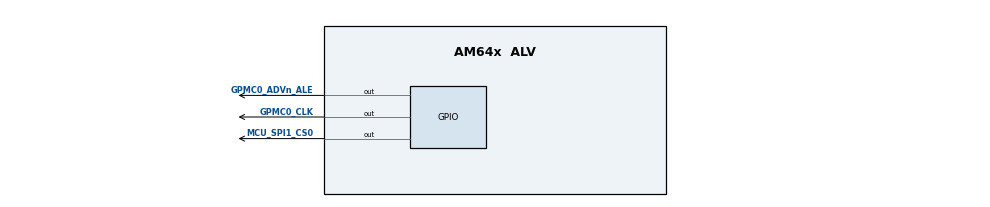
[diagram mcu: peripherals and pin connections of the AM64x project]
/**
 * @cliArgs --device "AM64x" --package "ALV" --part "Default" --context "r5fss0-0" --product "MCU_PLUS_SDK@07.03.01"
 * @versions {"tool":"1.20.0+3587"}
 */

/**
 * Import the modules used in this configuration.
 */
const eeprom     = scripting.addModule("/board/eeprom/eeprom", {}, false);
const eeprom1    = eeprom.addInstance();
const gpio       = scripting.addModule("/drivers/gpio/gpio", {}, false);
const gpio1      = gpio.addInstance();
const gpio2      = gpio.addInstance();
const gpio3      = gpio.addInstance();
const i2c        = scripting.addModule("/drivers/i2c/i2c", {}, false);
const i2c1       = i2c.addInstance();
const i2c2       = i2c.addInstance();
const ipc        = scripting.addModule("/drivers/ipc/ipc");
const pruicss    = scripting.addModule("/drivers/pruicss/pruicss", {}, false);
const pruicss1   = pruicss.addInstance();
const pruicss2   = pruicss.addInstance();
const debug_log  = scripting.addModule("/kernel/dpl/debug_log");
const dpl_cfg = scripting.addModule("/kernel/dpl/dpl_cfg");
const mpu_armv7  = scripting.addModule("/kernel/dpl/mpu_armv7", {}, false);
const mpu_armv71 = mpu_armv7.addInstance();
const mpu_armv72 = mpu_armv7.addInstance();
const mpu_armv73 = mpu_armv7.addInstance();
const mpu_armv74 = mpu_armv7.addInstance();
const mpu_armv75 = mpu_armv7.addInstance();
const mpu_armv76 = mpu_armv7.addInstance();
const mpu_armv77 = mpu_armv7.addInstance();
const mpu_armv78 = mpu_armv7.addInstance();
const enet_icss  = scripting.addModule("/networking/enet_icss/enet_icss", {}, false);
const enet_icss1 = enet_icss.addInstance();
const enet_icss2 = enet_icss.addInstance();
const enet_icss3 = enet_icss.addInstance();
const enet_icss4 = enet_icss.addInstance();

/**
 * Write custom configuration values to the imported modules.
 */
eeprom1.$name = "CONFIG_EEPROM0";

gpio1.$name                    = "CONFIG_GPIO0";
gpio1.pinDir                   = "OUTPUT";
gpio1.useMcuDomainPeripherals  = true;
gpio1.MCU_GPIO.$assign         = "MCU_GPIO0";
gpio1.MCU_GPIO.gpioPin.$assign = "MCU_SPI1_CS0";

gpio2.$name                = "CONFIG_GPIO_31";
gpio2.pinDir               = "OUTPUT";
gpio2.GPIO.$assign         = "GPIO0";
gpio2.GPIO.gpioPin.pu_pd   = "pu";
gpio2.GPIO.gpioPin.$assign = "GPMC0_CLK";

gpio3.$name                = "CONFIG_GPIO_32";
gpio3.pinDir               = "OUTPUT";
gpio3.GPIO.$assign         = "GPIO0";
gpio3.GPIO.gpioPin.pu_pd   = "pu";
gpio3.GPIO.gpioPin.$assign = "GPMC0_ADVn_ALE";

i2c1.$name               = "CONFIG_I2C0";
eeprom1.peripheralDriver = i2c1;
i2c1.I2C.$assign         = "I2C0";
i2c1.I2C.SCL.$assign     = "I2C0_SCL";
i2c1.I2C.SDA.$assign     = "I2C0_SDA";
i2c1.I2C_child.$name     = "drivers_i2c_v0_i2c_v0_template1";

i2c2.$name           = "CONFIG_I2C1";
i2c2.I2C.$assign     = "I2C1";
i2c2.I2C.SCL.$assign = "I2C1_SCL";
i2c2.I2C.SDA.$assign = "I2C1_SDA";
i2c2.I2C_child.$name = "drivers_i2c_v0_i2c_v0_template2";

ipc.r5fss1_0     = "NONE";
ipc.r5fss1_1     = "NONE";
ipc.m4fss0_0     = "NONE";
ipc.vringMsgSize = 1024;

debug_log.enableCssLog  = false;
debug_log.enableUartLog = true;
debug_log.uartLog.$name = "CONFIG_UART0";

const uart_v0_template  = scripting.addModule("/drivers/uart/v0/uart_v0_template", {}, false);
const uart_v0_template1 = uart_v0_template.addInstance({}, false);
uart_v0_template1.$name = "drivers_uart_v0_uart_v0_template0";
debug_log.uartLog.child = uart_v0_template1;

mpu_armv71.$name             = "CONFIG_MPU_REGION0";
mpu_armv71.size              = 31;
mpu_armv71.attributes        = "Device";
mpu_armv71.accessPermissions = "Supervisor RD+WR, User RD";
mpu_armv71.allowExecute      = false;

mpu_armv72.$name             = "CONFIG_MPU_REGION1";
mpu_armv72.size              = 15;
mpu_armv72.accessPermissions = "Supervisor RD+WR, User RD";

mpu_armv73.$name             = "CONFIG_MPU_REGION2";
mpu_armv73.baseAddr          = 0x41010000;
mpu_armv73.size              = 15;
mpu_armv73.accessPermissions = "Supervisor RD+WR, User RD";

mpu_armv74.$name             = "CONFIG_MPU_REGION3";
mpu_armv74.accessPermissions = "Supervisor RD+WR, User RD";
mpu_armv74.baseAddr          = 0x70000000;
mpu_armv74.attributes        = "NonCached";
mpu_armv74.size              = 21;

mpu_armv75.$name             = "CONFIG_MPU_REGION4";
mpu_armv75.accessPermissions = "Supervisor RD+WR, User RD";
mpu_armv75.baseAddr          = 0x80000000;
mpu_armv75.size              = 31;

mpu_armv76.$name             = "CONFIG_MPU_REGION5";
mpu_armv76.accessPermissions = "Supervisor RD+WR, User RD";
mpu_armv76.baseAddr          = 0xA5000000;
mpu_armv76.size              = 23;
mpu_armv76.attributes        = "NonCached";

mpu_armv77.$name    = "CONFIG_MPU_REGION6";
mpu_armv77.size     = 27;
mpu_armv77.baseAddr = 0x60000000;

mpu_armv78.$name      = "CONFIG_MPU_REGION7";
mpu_armv78.attributes = "NonCached";
mpu_armv78.size       = 16;
mpu_armv78.baseAddr   = 0x701D0000;

enet_icss1.$name                        = "CONFIG_ENET_ICSS0";
enet_icss1.LargePoolPktCount            = 16;
enet_icss1.PktInfoOnlyEnable            = true;
enet_icss1.mdioPollEnMask               = [];
enet_icss1.mdioMode                     = "MDIO_MODE_NORMAL";
enet_icss1.mode                         = "DUAL MAC";
enet_icss1.phyToMacInterfaceMode        = "RGMII";
enet_icss1.txDmaChannel[0].$name        = "ENET_DMA_TX_CH1";
enet_icss1.netifInstance.create(1);
enet_icss1.netifInstance[0].$name       = "NETIF_INST_ID0";
enet_icss1.rxDmaChannel[0].$name        = "ENET_DMA_RX_CH0";
enet_icss1.rxDmaChannel[0].PacketsCount = 16;

enet_icss2.$name                        = "CONFIG_ENET_ICSS1";
enet_icss2.LargePoolPktCount            = 16;
enet_icss2.PktInfoOnlyEnable            = true;
enet_icss2.mode                         = "DUAL MAC";
enet_icss2.mdioMdcEnable                = false;
enet_icss2.dualMacPortSelected          = "ENET_MAC_PORT_2";
enet_icss2.phyToMacInterfaceMode        = "RGMII";
enet_icss2.mdioPollEnMask               = [];
enet_icss2.mdioMode                     = "MDIO_MODE_NORMAL";
enet_icss2.txDmaChannel[0].$name        = "ENET_DMA_TX_CH0";
enet_icss2.netifInstance.create(1);
enet_icss2.netifInstance[0].$name       = "NETIF_INST_ID1";
enet_icss2.rxDmaChannel[0].$name        = "ENET_DMA_RX_CH1";
enet_icss2.rxDmaChannel[0].PacketsCount = 16;

pruicss2.$name                           = "CONFIG_PRU_ICSS1";
pruicss2.instance                        = "ICSSG1";
pruicss2.coreClk                         = 250000000;
enet_icss1.icss                          = pruicss2;
enet_icss2.icss                          = pruicss2;
pruicss2.AdditionalICSSSettings[0].$name = "CONFIG_PRU_ICSS_IO2";
pruicss2.intcMapping.create(2);
pruicss2.intcMapping[0].$name            = "CONFIG_ICSS1_INTC_MAPPING0";
pruicss2.intcMapping[0].event            = "41";
pruicss2.intcMapping[0].channel          = "7";
pruicss2.intcMapping[1].$name            = "CONFIG_ICSS1_INTC_MAPPING1";
pruicss2.intcMapping[1].event            = "53";
pruicss2.intcMapping[1].channel          = "7";

enet_icss3.$name                              = "CONFIG_ENET_ICSS2";
enet_icss3.mode                               = "DUAL MAC";
enet_icss3.PktInfoOnlyEnable                  = true;
enet_icss3.LargePoolPktCount                  = 16;
enet_icss3.instance                           = "ICSSG0";
enet_icss3.mdioPollEnMask                     = [];
enet_icss3.mdioMode                           = "MDIO_MODE_NORMAL";
enet_icss3.phyAddr1                           = 1;
enet_icss3.GigabitSupportEnable               = false;
enet_icss3.txDmaChannel[0].$name              = "ENET_DMA_TX_CH2";
enet_icss3.netifInstance.create(1);
enet_icss3.netifInstance[0].$name             = "NETIF_INST_ID2";
enet_icss3.rxDmaChannel[0].$name              = "ENET_DMA_RX_CH4";
enet_icss3.rxDmaChannel[0].PacketsCount       = 16;
enet_icss3.PRU_ICSSG0_MII_G_RT.MII0_COL.$used = false;
enet_icss3.PRU_ICSSG0_MII_G_RT.MII0_CRS.$used = false;
enet_icss3.PRU_ICSSG0_MII_G_RT.MII1_COL.$used = false;
enet_icss3.PRU_ICSSG0_MII_G_RT.MII1_CRS.$used = false;

enet_icss4.$name                        = "CONFIG_ENET_ICSS3";
enet_icss4.mode                         = "DUAL MAC";
enet_icss4.mdioMdcEnable                = false;
enet_icss4.dualMacPortSelected          = "ENET_MAC_PORT_2";
enet_icss4.LargePoolPktCount            = 16;
enet_icss4.PktInfoOnlyEnable            = true;
enet_icss4.instance                     = "ICSSG0";
enet_icss4.mdioPollEnMask               = [];
enet_icss4.mdioMode                     = "MDIO_MODE_NORMAL";
enet_icss4.phyAddr1                     = 1;
enet_icss4.GigabitSupportEnable         = false;
enet_icss4.txDmaChannel[0].$name        = "ENET_DMA_TX_CH3";
enet_icss4.netifInstance.create(1);
enet_icss4.netifInstance[0].$name       = "NETIF_INST_ID3";
enet_icss4.rxDmaChannel[0].$name        = "ENET_DMA_RX_CH5";
enet_icss4.rxDmaChannel[0].PacketsCount = 16;

pruicss1.$name                           = "CONFIG_PRU_ICSS0";
pruicss1.coreClk                         = 250000000;
enet_icss3.icss                          = pruicss1;
enet_icss4.icss                          = pruicss1;
pruicss1.AdditionalICSSSettings[0].$name = "CONFIG_PRU_ICSS_IO1";
pruicss1.intcMapping.create(2);
pruicss1.intcMapping[0].$name            = "CONFIG_ICSS0_INTC_MAPPING0";
pruicss1.intcMapping[0].event            = "41";
pruicss1.intcMapping[0].channel          = "7";
pruicss1.intcMapping[1].$name            = "CONFIG_ICSS0_INTC_MAPPING1";
pruicss1.intcMapping[1].event            = "53";
pruicss1.intcMapping[1].channel          = "7";

const udma         = scripting.addModule("/drivers/udma/udma", {}, false);
const udma1        = udma.addInstance({}, false);
enet_icss1.udmaDrv = udma1;
enet_icss2.udmaDrv = udma1;
enet_icss3.udmaDrv = udma1;
enet_icss4.udmaDrv = udma1;

/**
 * Pinmux solution for unlocked pins/peripherals. This ensures that minor changes to the automatic solver in a future
 * version of the tool will not impact the pinmux you originally saw.  These lines can be completely deleted in order to
 * re-solve from scratch.
 */
debug_log.uartLog.UART.$suggestSolution                     = "USART0";
debug_log.uartLog.UART.RXD.$suggestSolution                 = "UART0_RXD";
debug_log.uartLog.UART.TXD.$suggestSolution                 = "UART0_TXD";
enet_icss1.PRU_ICSSG1_MDIO.$suggestSolution                 = "PRU_ICSSG1_MDIO0";
enet_icss1.PRU_ICSSG1_MDIO.MDC.$suggestSolution             = "PRG1_MDIO0_MDC";
enet_icss1.PRU_ICSSG1_MDIO.MDIO.$suggestSolution            = "PRG1_MDIO0_MDIO";
enet_icss1.PRU_ICSSG1_IEP.$suggestSolution                  = "PRU_ICSSG1_IEP0";
enet_icss1.PRU_ICSSG1_IEP.EDC_LATCH_IN0.$suggestSolution    = "PRG1_PRU0_GPO18";
enet_icss1.PRU_ICSSG1_IEP.EDC_SYNC_OUT0.$suggestSolution    = "PRG1_PRU0_GPO19";
enet_icss1.PRU_ICSSG1_RGMII1.$suggestSolution               = "PRU_ICSSG1_RGMII2";
enet_icss1.PRU_ICSSG1_RGMII1.RD0.$suggestSolution           = "PRG1_PRU1_GPO0";
enet_icss1.PRU_ICSSG1_RGMII1.RD1.$suggestSolution           = "PRG1_PRU1_GPO1";
enet_icss1.PRU_ICSSG1_RGMII1.RD2.$suggestSolution           = "PRG1_PRU1_GPO2";
enet_icss1.PRU_ICSSG1_RGMII1.RD3.$suggestSolution           = "PRG1_PRU1_GPO3";
enet_icss1.PRU_ICSSG1_RGMII1.RXC.$suggestSolution           = "PRG1_PRU1_GPO6";
enet_icss1.PRU_ICSSG1_RGMII1.RX_CTL.$suggestSolution        = "PRG1_PRU1_GPO4";
enet_icss1.PRU_ICSSG1_RGMII1.TD0.$suggestSolution           = "PRG1_PRU1_GPO11";
enet_icss1.PRU_ICSSG1_RGMII1.TD1.$suggestSolution           = "PRG1_PRU1_GPO12";
enet_icss1.PRU_ICSSG1_RGMII1.TD2.$suggestSolution           = "PRG1_PRU1_GPO13";
enet_icss1.PRU_ICSSG1_RGMII1.TD3.$suggestSolution           = "PRG1_PRU1_GPO14";
enet_icss1.PRU_ICSSG1_RGMII1.TXC.$suggestSolution           = "PRG1_PRU1_GPO16";
enet_icss1.PRU_ICSSG1_RGMII1.TX_CTL.$suggestSolution        = "PRG1_PRU1_GPO15";
enet_icss2.PRU_ICSSG1_RGMII2.$suggestSolution               = "PRU_ICSSG1_RGMII1";
enet_icss2.PRU_ICSSG1_RGMII2.RD0.$suggestSolution           = "PRG1_PRU0_GPO0";
enet_icss2.PRU_ICSSG1_RGMII2.RD1.$suggestSolution           = "PRG1_PRU0_GPO1";
enet_icss2.PRU_ICSSG1_RGMII2.RD2.$suggestSolution           = "PRG1_PRU0_GPO2";
enet_icss2.PRU_ICSSG1_RGMII2.RD3.$suggestSolution           = "PRG1_PRU0_GPO3";
enet_icss2.PRU_ICSSG1_RGMII2.RXC.$suggestSolution           = "PRG1_PRU0_GPO6";
enet_icss2.PRU_ICSSG1_RGMII2.RX_CTL.$suggestSolution        = "PRG1_PRU0_GPO4";
enet_icss2.PRU_ICSSG1_RGMII2.TD0.$suggestSolution           = "PRG1_PRU0_GPO11";
enet_icss2.PRU_ICSSG1_RGMII2.TD1.$suggestSolution           = "PRG1_PRU0_GPO12";
enet_icss2.PRU_ICSSG1_RGMII2.TD2.$suggestSolution           = "PRG1_PRU0_GPO13";
enet_icss2.PRU_ICSSG1_RGMII2.TD3.$suggestSolution           = "PRG1_PRU0_GPO14";
enet_icss2.PRU_ICSSG1_RGMII2.TXC.$suggestSolution           = "PRG1_PRU0_GPO16";
enet_icss2.PRU_ICSSG1_RGMII2.TX_CTL.$suggestSolution        = "PRG1_PRU0_GPO15";
enet_icss3.PRU_ICSSG0_MDIO.$suggestSolution                 = "PRU_ICSSG0_MDIO0";
enet_icss3.PRU_ICSSG0_MDIO.MDC.$suggestSolution             = "PRG0_MDIO0_MDC";
enet_icss3.PRU_ICSSG0_MDIO.MDIO.$suggestSolution            = "PRG0_MDIO0_MDIO";
enet_icss3.PRU_ICSSG0_IEP.$suggestSolution                  = "PRU_ICSSG0_IEP0";
enet_icss3.PRU_ICSSG0_IEP.EDC_LATCH_IN0.$suggestSolution    = "PRG0_PRU0_GPO18";
enet_icss3.PRU_ICSSG0_IEP.EDC_SYNC_OUT0.$suggestSolution    = "PRG0_PRU0_GPO19";
enet_icss3.PRU_ICSSG0_MII_G_RT.$suggestSolution             = "PRU_ICSSG0_MII_G_RT";
enet_icss3.PRU_ICSSG0_MII_G_RT.MII0_RXD0.$suggestSolution   = "PRG0_PRU0_GPO0";
enet_icss3.PRU_ICSSG0_MII_G_RT.MII0_RXD1.$suggestSolution   = "PRG0_PRU0_GPO1";
enet_icss3.PRU_ICSSG0_MII_G_RT.MII0_RXD2.$suggestSolution   = "PRG0_PRU0_GPO2";
enet_icss3.PRU_ICSSG0_MII_G_RT.MII0_RXD3.$suggestSolution   = "PRG0_PRU0_GPO3";
enet_icss3.PRU_ICSSG0_MII_G_RT.MII0_RXDV.$suggestSolution   = "PRG0_PRU0_GPO4";
enet_icss3.PRU_ICSSG0_MII_G_RT.MII0_RXER.$suggestSolution   = "PRG0_PRU0_GPO5";
enet_icss3.PRU_ICSSG0_MII_G_RT.MII0_RXLINK.$suggestSolution = "PRG0_PRU0_GPO8";
enet_icss3.PRU_ICSSG0_MII_G_RT.MII0_TXD0.$suggestSolution   = "PRG0_PRU0_GPO11";
enet_icss3.PRU_ICSSG0_MII_G_RT.MII0_TXD1.$suggestSolution   = "PRG0_PRU0_GPO12";
enet_icss3.PRU_ICSSG0_MII_G_RT.MII0_TXD2.$suggestSolution   = "PRG0_PRU0_GPO13";
enet_icss3.PRU_ICSSG0_MII_G_RT.MII0_TXD3.$suggestSolution   = "PRG0_PRU0_GPO14";
enet_icss3.PRU_ICSSG0_MII_G_RT.MII0_TXEN.$suggestSolution   = "PRG0_PRU0_GPO15";
enet_icss3.PRU_ICSSG0_MII_G_RT.MII1_RXD0.$suggestSolution   = "PRG0_PRU1_GPO0";
enet_icss3.PRU_ICSSG0_MII_G_RT.MII1_RXD1.$suggestSolution   = "PRG0_PRU1_GPO1";
enet_icss3.PRU_ICSSG0_MII_G_RT.MII1_RXD2.$suggestSolution   = "PRG0_PRU1_GPO2";
enet_icss3.PRU_ICSSG0_MII_G_RT.MII1_RXD3.$suggestSolution   = "PRG0_PRU1_GPO3";
enet_icss3.PRU_ICSSG0_MII_G_RT.MII1_RXDV.$suggestSolution   = "PRG0_PRU1_GPO4";
enet_icss3.PRU_ICSSG0_MII_G_RT.MII1_RXER.$suggestSolution   = "PRG0_PRU1_GPO5";
enet_icss3.PRU_ICSSG0_MII_G_RT.MII1_RXLINK.$suggestSolution = "PRG0_PRU1_GPO8";
enet_icss3.PRU_ICSSG0_MII_G_RT.MII1_TXD0.$suggestSolution   = "PRG0_PRU1_GPO11";
enet_icss3.PRU_ICSSG0_MII_G_RT.MII1_TXD1.$suggestSolution   = "PRG0_PRU1_GPO12";
enet_icss3.PRU_ICSSG0_MII_G_RT.MII1_TXD2.$suggestSolution   = "PRG0_PRU1_GPO13";
enet_icss3.PRU_ICSSG0_MII_G_RT.MII1_TXD3.$suggestSolution   = "PRG0_PRU1_GPO14";
enet_icss3.PRU_ICSSG0_MII_G_RT.MII1_TXEN.$suggestSolution   = "PRG0_PRU1_GPO15";
enet_icss3.PRU_ICSSG0_MII_G_RT.MII_MR0_CLK.$suggestSolution = "PRG0_PRU0_GPO6";
enet_icss3.PRU_ICSSG0_MII_G_RT.MII_MR1_CLK.$suggestSolution = "PRG0_PRU1_GPO6";
enet_icss3.PRU_ICSSG0_MII_G_RT.MII_MT0_CLK.$suggestSolution = "PRG0_PRU0_GPO16";
enet_icss3.PRU_ICSSG0_MII_G_RT.MII_MT1_CLK.$suggestSolution = "PRG0_PRU1_GPO16";
